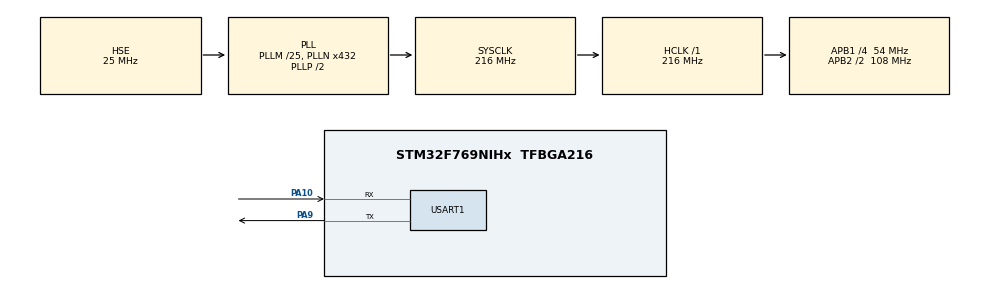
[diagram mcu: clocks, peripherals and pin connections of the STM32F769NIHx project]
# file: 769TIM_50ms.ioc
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Mcu.Family=STM32F7
Mcu.Name=STM32F769NIHx
Mcu.Package=TFBGA216
NVIC.PriorityGroup=NVIC_PRIORITYGROUP_4
NVIC.TIM6_DAC_IRQn=true\:0\:0\:false\:false\:true\:true\:true\:true
NVIC.TIM7_IRQn=true\:0\:0\:false\:false\:true\:true\:true\:true
PA10.Mode=Asynchronous
PA10.Signal=USART1_RX
PA9.Mode=Asynchronous
PA9.Signal=USART1_TX
PH0/OSC_IN.Mode=HSE-External-Oscillator
PH0/OSC_IN.Signal=RCC_OSC_IN
PH1/OSC_OUT.Mode=HSE-External-Oscillator
PH1/OSC_OUT.Signal=RCC_OSC_OUT
ProjectManager.HeapSize=0x200
ProjectManager.StackSize=0x400
ProjectManager.TargetToolchain=EWARM V8.50
RCC.AHBFreq_Value=216000000
RCC.APB1CLKDivider=RCC_HCLK_DIV4
RCC.APB1Freq_Value=54000000
RCC.APB1TimFreq_Value=108000000
RCC.APB2CLKDivider=RCC_HCLK_DIV2
RCC.APB2Freq_Value=108000000
RCC.APB2TimFreq_Value=216000000
RCC.CortexFreq_Value=216000000
RCC.HCLKFreq_Value=216000000
RCC.HSE_VALUE=25000000
RCC.HSI_VALUE=16000000
RCC.LSE_VALUE=32768
RCC.PLLM=25
RCC.PLLN=432
RCC.PLLSourceVirtual=RCC_PLLSOURCE_HSE
RCC.SYSCLKFreq_VALUE=216000000
RCC.SYSCLKSource=RCC_SYSCLKSOURCE_PLLCLK
RCC.USBFreq_Value=216000000
RCC.VCOOutputFreq_Value=432000000
TIM6.Period=5400-1
TIM6.Prescaler=100-1
TIM7.Period=5400-1
TIM7.Prescaler=5000-1
USART1.VirtualMode-Asynchronous=VM_ASYNC
VP_TIM6_VS_ClockSourceINT.Mode=Enable_Timer
VP_TIM7_VS_ClockSourceINT.Mode=Enable_Timer
board=custom

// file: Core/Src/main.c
/* USER CODE BEGIN Header */
/**
******************************************************************************
* @file           : main.c
* @brief          : Main program body
******************************************************************************
* @attention
*
* Copyright (c) 2023 STMicroelectronics.
* All rights reserved.
*
* This software is licensed under terms that can be found in the LICENSE file
* in the root directory of this software component.
* If no LICENSE file comes with this software, it is provided AS-IS.
*
******************************************************************************
*/
/* USER CODE END Header */
#include "main.h"

/* USER CODE BEGIN Includes */
#include <stdio.h>
#include <string.h>
/* USER CODE END Includes */

TIM_HandleTypeDef htim6;
TIM_HandleTypeDef htim7;

UART_HandleTypeDef huart1;

/* USER CODE BEGIN PV */
int g_iFlag = 0;
int g_iTim7Flag = 0;
int g_iInputFlag = 0;
int g_aChFlag[8] = {0, 0, 0, 0, 0, 0, 0, 0};
int g_aChCnt[8] = {0, 0, 0, 0, 0, 0, 0, 0};
/* USER CODE END PV */

void SystemClock_Config(void);
static void MPU_Config(void);
static void MX_GPIO_Init(void);
static void MX_TIM6_Init(void);
static void MX_USART1_UART_Init(void);
static void MX_TIM7_Init(void);

int main(void)
{

    /* MPU Configuration--------------------------------------------------------*/
    MPU_Config();

    /* MCU Configuration--------------------------------------------------------*/

    /* Reset of all peripherals, Initializes the Flash interface and the Systick. */
    HAL_Init();

    /* Configure the system clock */
    SystemClock_Config();

    /* Initialize all configured peripherals */
    MX_GPIO_Init();
    MX_TIM6_Init();
    MX_USART1_UART_Init();
    MX_TIM7_Init();
    /* USER CODE BEGIN 2 */
    uint8_t g_iUartRx;
    char buf[256];
    HAL_TIM_Base_Start_IT(&htim6);
    HAL_TIM_Base_Start_IT(&htim7);

    /* USER CODE END 2 */

    /* Infinite loop */
    while (1)
    {

        /* USER CODE BEGIN 3 */
        HAL_UART_Receive(&huart1, &g_iUartRx, sizeof(g_iUartRx), 10);
        switch(g_iUartRx)
        {
        case '1':
            g_aChFlag[0] = 1;
            break;
        case '2':
            g_aChFlag[1] = 1;
            break;
        case '3':
            g_aChFlag[2] = 1;
            break;
        case '4':
            g_aChFlag[3] = 1;
            break;
        case '5':
            g_aChFlag[4] = 1;
            break;
        case '6':
            g_aChFlag[5] = 1;
            break;
        case '7':
            g_aChFlag[6] = 1;
            break;
        case '8':
            g_aChFlag[7] = 1;
            break;
        }
        g_iUartRx = 0;

        if(g_iTim7Flag == 1)
        {
            for(int i = 0; i < 7; i++)
            {
                sprintf(buf, "%d ", g_aChCnt[i]);
                HAL_UART_Transmit(&huart1, (uint8_t*)buf, strlen(buf), 10);
                if(i == 6)
                {
                    sprintf(buf, "\r\n");
                    HAL_UART_Transmit(&huart1, (uint8_t*)buf, strlen(buf), 10);
                }
            }
            g_iTim7Flag = 0;
        }

        if(g_iFlag == 1)
        {
            for(int i = 0; i < 8; i++)
            {
                if(g_aChFlag[i] == 1)
                    g_aChCnt[i]++;
                if(g_aChCnt[i] == 5)
                {
                    g_aChCnt[i] = 0;
                    g_aChFlag[i] = 0;
                }
            }
            g_iFlag = 0;
        }
        /* USER CODE END 3 */
    }
}

void SystemClock_Config(void)
{
    RCC_OscInitTypeDef RCC_OscInitStruct = {0};
    RCC_ClkInitTypeDef RCC_ClkInitStruct = {0};

    /** Configure the main internal regulator output voltage
    */
    __HAL_RCC_PWR_CLK_ENABLE();
    __HAL_PWR_VOLTAGESCALING_CONFIG(PWR_REGULATOR_VOLTAGE_SCALE1);

    /** Initializes the RCC Oscillators according to the specified parameters
    * in the RCC_OscInitTypeDef structure.
    */
    RCC_OscInitStruct.OscillatorType = RCC_OSCILLATORTYPE_HSE;
    RCC_OscInitStruct.HSEState = RCC_HSE_ON;
    RCC_OscInitStruct.PLL.PLLState = RCC_PLL_ON;
    RCC_OscInitStruct.PLL.PLLSource = RCC_PLLSOURCE_HSE;
    RCC_OscInitStruct.PLL.PLLM = 25;
    RCC_OscInitStruct.PLL.PLLN = 432;
    RCC_OscInitStruct.PLL.PLLP = RCC_PLLP_DIV2;
    RCC_OscInitStruct.PLL.PLLQ = 2;
    RCC_OscInitStruct.PLL.PLLR = 2;
    if (HAL_RCC_OscConfig(&RCC_OscInitStruct) != HAL_OK)
    {
        Error_Handler();
    }

    /** Activate the Over-Drive mode
    */
    if (HAL_PWREx_EnableOverDrive() != HAL_OK)
    {
        Error_Handler();
    }

    /** Initializes the CPU, AHB and APB buses clocks
    */
    RCC_ClkInitStruct.ClockType = RCC_CLOCKTYPE_HCLK|RCC_CLOCKTYPE_SYSCLK
        |RCC_CLOCKTYPE_PCLK1|RCC_CLOCKTYPE_PCLK2;
    RCC_ClkInitStruct.SYSCLKSource = RCC_SYSCLKSOURCE_PLLCLK;
    RCC_ClkInitStruct.AHBCLKDivider = RCC_SYSCLK_DIV1;
    RCC_ClkInitStruct.APB1CLKDivider = RCC_HCLK_DIV4;
    RCC_ClkInitStruct.APB2CLKDivider = RCC_HCLK_DIV2;

    if (HAL_RCC_ClockConfig(&RCC_ClkInitStruct, FLASH_LATENCY_7) != HAL_OK)
    {
        Error_Handler();
    }
}

static void MX_TIM6_Init(void)
{

    TIM_MasterConfigTypeDef sMasterConfig = {0};

    htim6.Instance = TIM6;
    htim6.Init.Prescaler = 100-1;
    htim6.Init.CounterMode = TIM_COUNTERMODE_UP;
    htim6.Init.Period = 5400-1;
    htim6.Init.AutoReloadPreload = TIM_AUTORELOAD_PRELOAD_DISABLE;
    if (HAL_TIM_Base_Init(&htim6) != HAL_OK)
    {
        Error_Handler();
    }
    sMasterConfig.MasterOutputTrigger = TIM_TRGO_RESET;
    sMasterConfig.MasterSlaveMode = TIM_MASTERSLAVEMODE_DISABLE;
    if (HAL_TIMEx_MasterConfigSynchronization(&htim6, &sMasterConfig) != HAL_OK)
    {
        Error_Handler();
    }

}

static void MX_TIM7_Init(void)
{

    TIM_MasterConfigTypeDef sMasterConfig = {0};

    htim7.Instance = TIM7;
    htim7.Init.Prescaler = 5000-1;
    htim7.Init.CounterMode = TIM_COUNTERMODE_UP;
    htim7.Init.Period = 5400-1;
    htim7.Init.AutoReloadPreload = TIM_AUTORELOAD_PRELOAD_DISABLE;
    if (HAL_TIM_Base_Init(&htim7) != HAL_OK)
    {
        Error_Handler();
    }
    sMasterConfig.MasterOutputTrigger = TIM_TRGO_RESET;
    sMasterConfig.MasterSlaveMode = TIM_MASTERSLAVEMODE_DISABLE;
    if (HAL_TIMEx_MasterConfigSynchronization(&htim7, &sMasterConfig) != HAL_OK)
    {
        Error_Handler();
    }

}

static void MX_USART1_UART_Init(void)
{

    huart1.Instance = USART1;
    huart1.Init.BaudRate = 115200;
    huart1.Init.WordLength = UART_WORDLENGTH_8B;
    huart1.Init.StopBits = UART_STOPBITS_1;
    huart1.Init.Parity = UART_PARITY_NONE;
    huart1.Init.Mode = UART_MODE_TX_RX;
    huart1.Init.HwFlowCtl = UART_HWCONTROL_NONE;
    huart1.Init.OverSampling = UART_OVERSAMPLING_16;
    huart1.Init.OneBitSampling = UART_ONE_BIT_SAMPLE_DISABLE;
    huart1.AdvancedInit.AdvFeatureInit = UART_ADVFEATURE_NO_INIT;
    if (HAL_UART_Init(&huart1) != HAL_OK)
    {
        Error_Handler();
    }

}

static void MX_GPIO_Init(void)
{

    /* GPIO Ports Clock Enable */
    __HAL_RCC_GPIOA_CLK_ENABLE();
    __HAL_RCC_GPIOH_CLK_ENABLE();

}

/* USER CODE BEGIN 4 */
void HAL_TIM_PeriodElapsedCallback(TIM_HandleTypeDef *htim)
{
    if(htim->Instance == TIM6)
    {
        g_iFlag = 1;
    }
    if(htim->Instance == TIM7)
    {
        g_iTim7Flag = 1;
    }
}
/* USER CODE END 4 */

/* MPU Configuration */

void MPU_Config(void)
{
    MPU_Region_InitTypeDef MPU_InitStruct = {0};

    /* Disables the MPU */
    HAL_MPU_Disable();

    /** Initializes and configures the Region and the memory to be protected
    */
    MPU_InitStruct.Enable = MPU_REGION_ENABLE;
    MPU_InitStruct.Number = MPU_REGION_NUMBER0;
    MPU_InitStruct.BaseAddress = 0x0;
    MPU_InitStruct.Size = MPU_REGION_SIZE_4GB;
    MPU_InitStruct.SubRegionDisable = 0x87;
    MPU_InitStruct.TypeExtField = MPU_TEX_LEVEL0;
    MPU_InitStruct.AccessPermission = MPU_REGION_NO_ACCESS;
    MPU_InitStruct.DisableExec = MPU_INSTRUCTION_ACCESS_DISABLE;
    MPU_InitStruct.IsShareable = MPU_ACCESS_SHAREABLE;
    MPU_InitStruct.IsCacheable = MPU_ACCESS_NOT_CACHEABLE;
    MPU_InitStruct.IsBufferable = MPU_ACCESS_NOT_BUFFERABLE;

    HAL_MPU_ConfigRegion(&MPU_InitStruct);
    /* Enables the MPU */
    HAL_MPU_Enable(MPU_PRIVILEGED_DEFAULT);

}

void Error_Handler(void)
{
    __disable_irq();
    while (1)
    {
    }
}
